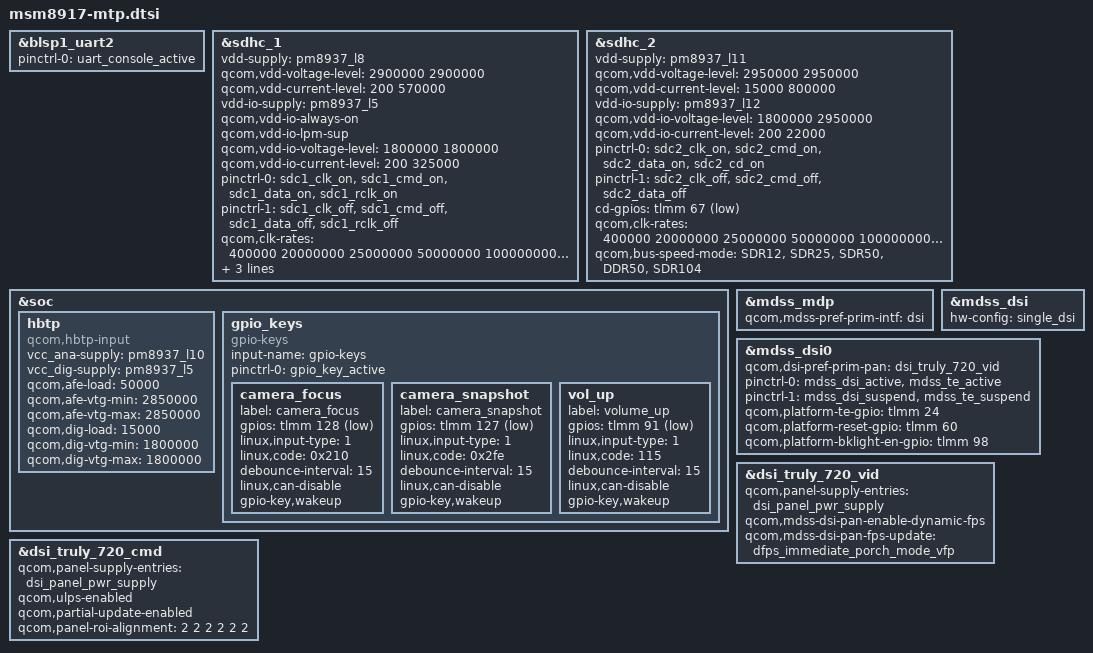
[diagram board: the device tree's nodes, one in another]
/*
 * Copyright (c) 2015-2018, The Linux Foundation. All rights reserved.
 *
 * This program is free software; you can redistribute it and/or modify
 * it under the terms of the GNU General Public License version 2 and
 * only version 2 as published by the Free Software Foundation.
 *
 * This program is distributed in the hope that it will be useful,
 * but WITHOUT ANY WARRANTY; without even the implied warranty of
 * MERCHANTABILITY or FITNESS FOR A PARTICULAR PURPOSE.  See the
 * GNU General Public License for more details.
 */

#include "msm8917-camera-sensor-mtp.dtsi"

&blsp1_uart2 {
	status = "ok";
	pinctrl-names = "default";
	pinctrl-0 = <&uart_console_active>;
};

&sdhc_1 {
	/* device core power supply */
	vdd-supply = <&pm8937_l8>;
	qcom,vdd-voltage-level = <2900000 2900000>;
	qcom,vdd-current-level = <200 570000>;

	/* device communication power supply */
	vdd-io-supply = <&pm8937_l5>;
	qcom,vdd-io-always-on;
	qcom,vdd-io-lpm-sup;
	qcom,vdd-io-voltage-level = <1800000 1800000>;
	qcom,vdd-io-current-level = <200 325000>;

	pinctrl-names = "active", "sleep";
	pinctrl-0 = <&sdc1_clk_on &sdc1_cmd_on &sdc1_data_on &sdc1_rclk_on>;
	pinctrl-1 = <&sdc1_clk_off &sdc1_cmd_off &sdc1_data_off &sdc1_rclk_off>;

	qcom,clk-rates = <400000 20000000 25000000 50000000 100000000 192000000
								384000000>;
	qcom,nonremovable;
	qcom,bus-speed-mode = "HS400_1p8v", "HS200_1p8v", "DDR_1p8v";

	status = "ok";
};

&sdhc_2 {
	/* device core power supply */
	vdd-supply = <&pm8937_l11>;
	qcom,vdd-voltage-level = <2950000 2950000>;
	qcom,vdd-current-level = <15000 800000>;

	/* device communication power supply */
	vdd-io-supply = <&pm8937_l12>;
	qcom,vdd-io-voltage-level = <1800000 2950000>;
	qcom,vdd-io-current-level = <200 22000>;

	pinctrl-names = "active", "sleep";
	pinctrl-0 = <&sdc2_clk_on &sdc2_cmd_on &sdc2_data_on &sdc2_cd_on>;
	pinctrl-1 = <&sdc2_clk_off &sdc2_cmd_off &sdc2_data_off>;

	cd-gpios = <&tlmm 67 0x1>;

	qcom,clk-rates = <400000 20000000 25000000 50000000 100000000
								200000000>;
	qcom,bus-speed-mode = "SDR12", "SDR25", "SDR50", "DDR50", "SDR104";

	status = "ok";
};

&soc {
	hbtp {
		compatible = "qcom,hbtp-input";
		vcc_ana-supply = <&pm8937_l10>;
		vcc_dig-supply = <&pm8937_l5>;
		qcom,afe-load = <50000>;
		qcom,afe-vtg-min = <2850000>;
		qcom,afe-vtg-max = <2850000>;
		qcom,dig-load = <15000>;
		qcom,dig-vtg-min = <1800000>;
		qcom,dig-vtg-max = <1800000>;
	};

	gpio_keys {
		compatible = "gpio-keys";
		input-name = "gpio-keys";
		pinctrl-names = "default";
		pinctrl-0 = <&gpio_key_active>;

		camera_focus {
			label = "camera_focus";
			gpios = <&tlmm 128 0x1>;
			linux,input-type = <1>;
			linux,code = <0x210>;
			debounce-interval = <15>;
			linux,can-disable;
			gpio-key,wakeup;
		};

		camera_snapshot {
			label = "camera_snapshot";
			gpios = <&tlmm 127 0x1>;
			linux,input-type = <1>;
			linux,code = <0x2fe>;
			debounce-interval = <15>;
			linux,can-disable;
			gpio-key,wakeup;
		};

		vol_up {
			label = "volume_up";
			gpios = <&tlmm 91 0x1>;
			linux,input-type = <1>;
			linux,code = <115>;
			debounce-interval = <15>;
			linux,can-disable;
			gpio-key,wakeup;
		};
	};
};

#include "msm8937-mdss-panels.dtsi"

&mdss_mdp {
	qcom,mdss-pref-prim-intf = "dsi";
};

&mdss_dsi {
	hw-config = "single_dsi";
};

&mdss_dsi0 {
	qcom,dsi-pref-prim-pan = <&dsi_truly_720_vid>;
	pinctrl-names = "mdss_default", "mdss_sleep";
	pinctrl-0 = <&mdss_dsi_active &mdss_te_active>;
	pinctrl-1 = <&mdss_dsi_suspend &mdss_te_suspend>;
	qcom,platform-te-gpio = <&tlmm 24 0>;
	qcom,platform-reset-gpio = <&tlmm 60 0>;
	qcom,platform-bklight-en-gpio = <&tlmm 98 0>;
};

&dsi_truly_720_vid {
	qcom,panel-supply-entries = <&dsi_panel_pwr_supply>;
	qcom,mdss-dsi-pan-enable-dynamic-fps;
	qcom,mdss-dsi-pan-fps-update = "dfps_immediate_porch_mode_vfp";
};

&dsi_truly_720_cmd {
	qcom,panel-supply-entries = <&dsi_panel_pwr_supply>;
	qcom,ulps-enabled;
	qcom,partial-update-enabled;
	qcom,panel-roi-alignment = <2 2 2 2 2 2>;
};
